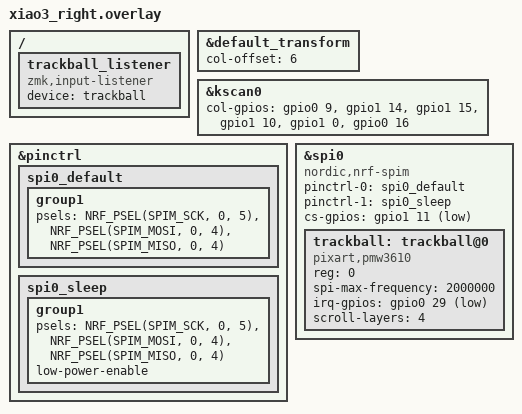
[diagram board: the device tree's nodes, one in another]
#include "xiao3.dtsi"

&default_transform {
    col-offset = <6>;
};

&kscan0 {
    col-gpios               // Col1-7 0.09 1.14 1.15 1.10 1.00 0.16 0.29**
        = <&gpio0 9 GPIO_ACTIVE_HIGH> 
        , <&gpio1 14 GPIO_ACTIVE_HIGH>
        , <&gpio1 15 GPIO_ACTIVE_HIGH>
        , <&gpio1 10 GPIO_ACTIVE_HIGH> 
        , <&gpio1 0 GPIO_ACTIVE_HIGH> 
        , <&gpio0 16 GPIO_ACTIVE_HIGH> 
//        , <&gpio0 29 GPIO_ACTIVE_HIGH> 
        ;
};


&pinctrl {
    spi0_default: spi0_default {
        group1 {
            psels = <NRF_PSEL(SPIM_SCK, 0, 5)>,
                <NRF_PSEL(SPIM_MOSI, 0, 4)>,
                <NRF_PSEL(SPIM_MISO, 0, 4)>;
        };
    };

    spi0_sleep: spi0_sleep {
        group1 {
            psels = <NRF_PSEL(SPIM_SCK, 0, 5)>,
                <NRF_PSEL(SPIM_MOSI, 0, 4)>,
                <NRF_PSEL(SPIM_MISO, 0, 4)>;
            low-power-enable;
        };
    };
};

&spi0 {
    status = "okay";
    compatible = "nordic,nrf-spim";
    pinctrl-0 = <&spi0_default>;
    pinctrl-1 = <&spi0_sleep>;
    pinctrl-names = "default", "sleep";
    cs-gpios = <&gpio1 11 GPIO_ACTIVE_LOW>; //TB1 nCS 1.11

    trackball: trackball@0 {
        status = "okay";
        compatible = "pixart,pmw3610";
        reg = <0>;
        spi-max-frequency = <2000000>;
        irq-gpios = <&gpio0 29 (GPIO_ACTIVE_LOW | GPIO_PULL_UP)>; //TB2 Mot 0.29
        scroll-layers = <4>;
    };
};

/ {
  trackball_listener {
    compatible = "zmk,input-listener";
    device = <&trackball>;

  };
};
